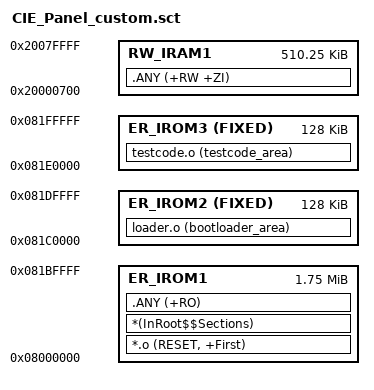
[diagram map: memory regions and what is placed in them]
; *************************************************************
; *** Scatter-Loading Description File generated by uVision ***
; *************************************************************

LR_IROM1 0x08000000 0x001C0000  {    ; load region size_region
  ER_IROM1 0x08000000 0x001C0000  {  ; load address = execution address
   *.o (RESET, +First)
   *(InRoot$$Sections)
   .ANY (+RO)
  }
  RW_IRAM1 0x20000700 0x0007F900  {  ; RW data		
   .ANY (+RW +ZI)
  }
} 

LR_IROM2 0x081C0000 0x00040000  {
  ER_IROM2 0x081C0000 FIXED 0x00020000 {  ; load address = execution address
  loader.o (bootloader_area)
  }
  ER_IROM3 0x081E0000 FIXED 0x00020000 {  ; load address = execution address
  testcode.o (testcode_area)
  }
}
